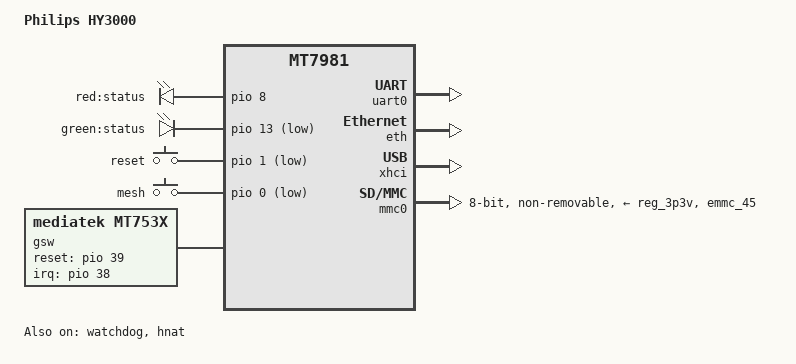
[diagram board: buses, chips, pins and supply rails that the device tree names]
/dts-v1/;
#include "mt7981.dtsi"

/ {
	model = "Philips HY3000";
	compatible = "philips,hy3000", "mediatek,mt7981";

	chosen {
		bootargs = "console=ttyS0,115200n1 loglevel=8 \
			    earlycon=uart8250,mmio32,0x11002000 \
			    root=PARTLABEL=rootfs rootwait rootfstype=squashfs,f2fs";
	};

	aliases {
		led-boot = &status_red_led;
		led-failsafe = &status_red_led;
		led-running = &status_green_led;
		led-upgrade = &status_red_led;
	};

	leds {
        compatible = "gpio-leds";

        status_red_led: led-0 {
                label = "red:status";
                gpios = <&pio 8 GPIO_ACTIVE_HIGH>;
        };

        status_green_led: led-1 {
                label = "green:status";
                gpios = <&pio 13 GPIO_ACTIVE_LOW>;
        };
	};

	gpio-keys {
		compatible = "gpio-keys";
        
		reset {
			label = "reset";
			linux,code = <KEY_RESTART>;
			gpios = <&pio 1 GPIO_ACTIVE_LOW>;
		};

		mesh {
			label = "mesh";
			gpios = <&pio 0 GPIO_ACTIVE_LOW>;
			linux,code = <BTN_9>;
			linux,input-type = <EV_SW>;
		};
	};
	
	gsw: gsw@0 {
		compatible = "mediatek,mt753x";
		mediatek,ethsys = <&ethsys>;
		#address-cells = <1>;
		#size-cells = <0>;
	};
};

&uart0 {
	status = "okay";
};

&watchdog {
	status = "okay";
};

&eth {
	status = "okay";

	gmac0: mac@0 {
		compatible = "mediatek,eth-mac";
		reg = <0>;
		phy-mode = "2500base-x";

		fixed-link {
			speed = <2500>;
			full-duplex;
			pause;
		};
	};

	gmac1: mac@1 {
		compatible = "mediatek,eth-mac";
		reg = <1>;
		phy-mode = "2500base-x";

		fixed-link {
			speed = <2500>;
			full-duplex;
			pause;
		};
	};

	mdio: mdio-bus {
		#address-cells = <1>;
		#size-cells = <0>;
	};
};

&gsw {
	mediatek,mdio = <&mdio>;
	mediatek,mdio_master_pinmux = <0>;
	reset-gpios = <&pio 39 0>;
	interrupt-parent = <&pio>;
	interrupts = <38 IRQ_TYPE_LEVEL_HIGH>;
	status = "okay";

	port5: port@5 {
		compatible = "mediatek,mt753x-port";
		reg = <5>;
		phy-mode = "sgmii";

		fixed-link {
			speed = <2500>;
			full-duplex;
		};
	};

	port6: port@6 {
		compatible = "mediatek,mt753x-port";
		mediatek,ssc-on;
		reg = <6>;
		phy-mode = "sgmii";

		fixed-link {
			speed = <2500>;
			full-duplex;
		};
	};
};

&hnat {
	mtketh-wan = "eth1";
	mtketh-lan = "eth0";
	mtketh-max-gmac = <2>;
	ext-devices-prefix = "usb", "wwan";
	status = "okay";
};

&xhci {
	status = "okay";
};

&mmc0 {
    bus-width = <8>;
	max-frequency = <52000000>;
	no-sd;
	no-sdio;
	cap-mmc-highspeed;
    pinctrl-names = "default", "state_uhs";
	pinctrl-0 = <&mmc0_pins_default>;
	pinctrl-1 = <&mmc0_pins_uhs>;
	vmmc-supply = <&reg_3p3v>;
	non-removable;
	status = "okay";
};

&pio {
	mmc0_pins_default: mmc0-pins-default {
		mux {
			function = "flash";
			groups = "emmc_45";
		};
	};

	mmc0_pins_uhs: mmc0-pins-uhs {
		mux {
			function = "flash";
			groups = "emmc_45";
		};
	};
};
